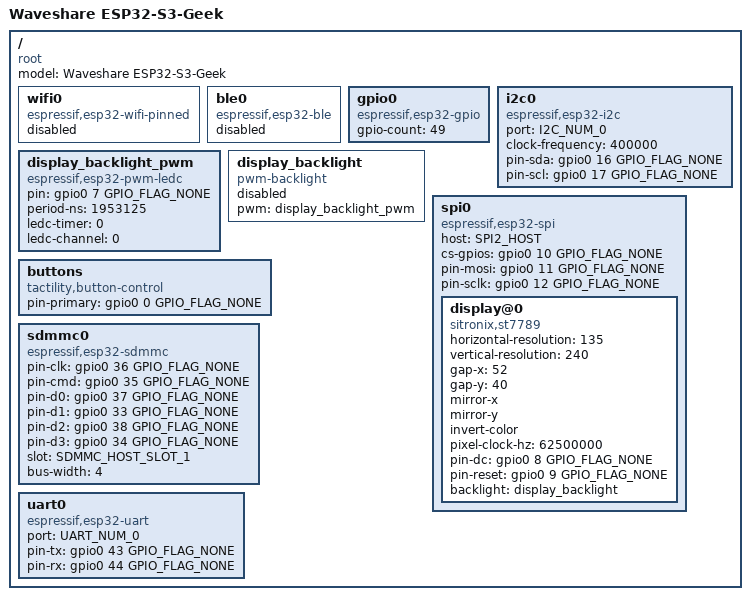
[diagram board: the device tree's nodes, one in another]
/dts-v1/;

#include <tactility/bindings/root.h>
#include <tactility/bindings/esp32_ble.h>
#include <tactility/bindings/esp32_wifi_pinned.h>
#include <tactility/bindings/esp32_gpio.h>
#include <tactility/bindings/esp32_i2c.h>
#include <tactility/bindings/esp32_sdmmc.h>
#include <tactility/bindings/esp32_spi.h>
#include <tactility/bindings/esp32_uart.h>
#include <tactility/bindings/esp32_pwm_ledc.h>
#include <tactility/bindings/pwm_backlight.h>

#include <bindings/st7789.h>
#include <bindings/button_control.h>

/ {
	compatible = "root";
	model = "Waveshare ESP32-S3-Geek";

	wifi0 {
		compatible = "espressif,esp32-wifi-pinned";
		status = "disabled";
	};

	ble0 {
		compatible = "espressif,esp32-ble";
		status = "disabled";
	};

	gpio0 {
		compatible = "espressif,esp32-gpio";
		gpio-count = <49>;
	};

	i2c0 {
		compatible = "espressif,esp32-i2c";
		port = <I2C_NUM_0>;
		clock-frequency = <400000>;
		pin-sda = <&gpio0 16 GPIO_FLAG_NONE>;
		pin-scl = <&gpio0 17 GPIO_FLAG_NONE>;
	};

	display_backlight_pwm {
		compatible = "espressif,esp32-pwm-ledc";
		pin = <&gpio0 7 GPIO_FLAG_NONE>;
		period-ns = <1953125>;
		ledc-timer = <0>;
		ledc-channel = <0>;
	};

	display_backlight {
		compatible = "pwm-backlight";
		// Off by default so display power-on won't show the screen from before the last power loss.
		// The display backlight is turned on during the boot process.
		status = "disabled";
		pwm = <&display_backlight_pwm>;
	};

	spi0 {
		compatible = "espressif,esp32-spi";
		host = <SPI2_HOST>;
		cs-gpios = <&gpio0 10 GPIO_FLAG_NONE>;
		pin-mosi = <&gpio0 11 GPIO_FLAG_NONE>;
		pin-sclk = <&gpio0 12 GPIO_FLAG_NONE>;

		display@0 {
			compatible = "sitronix,st7789";
			horizontal-resolution = <135>;
			vertical-resolution = <240>;
			gap-x = <52>;
			gap-y = <40>;
			mirror-x;
			mirror-y;
			invert-color;
			pixel-clock-hz = <62500000>;
			pin-dc = <&gpio0 8 GPIO_FLAG_NONE>;
			pin-reset = <&gpio0 9 GPIO_FLAG_NONE>;
			backlight = <&display_backlight>;
		};
	};

	buttons {
		compatible = "tactility,button-control";
		pin-primary = <&gpio0 0 GPIO_FLAG_NONE>;
	};

	sdmmc0 {
		compatible = "espressif,esp32-sdmmc";
		pin-clk = <&gpio0 36 GPIO_FLAG_NONE>;
		pin-cmd = <&gpio0 35 GPIO_FLAG_NONE>;
		pin-d0 = <&gpio0 37 GPIO_FLAG_NONE>;
		pin-d1 = <&gpio0 33 GPIO_FLAG_NONE>;
		pin-d2 = <&gpio0 38 GPIO_FLAG_NONE>;
		pin-d3 = <&gpio0 34 GPIO_FLAG_NONE>;
		slot = <SDMMC_HOST_SLOT_1>;
		bus-width = <4>;
	};

	uart0 {
		compatible = "espressif,esp32-uart";
		port = <UART_NUM_0>;
		pin-tx = <&gpio0 43 GPIO_FLAG_NONE>;
		pin-rx = <&gpio0 44 GPIO_FLAG_NONE>;
	};
};
